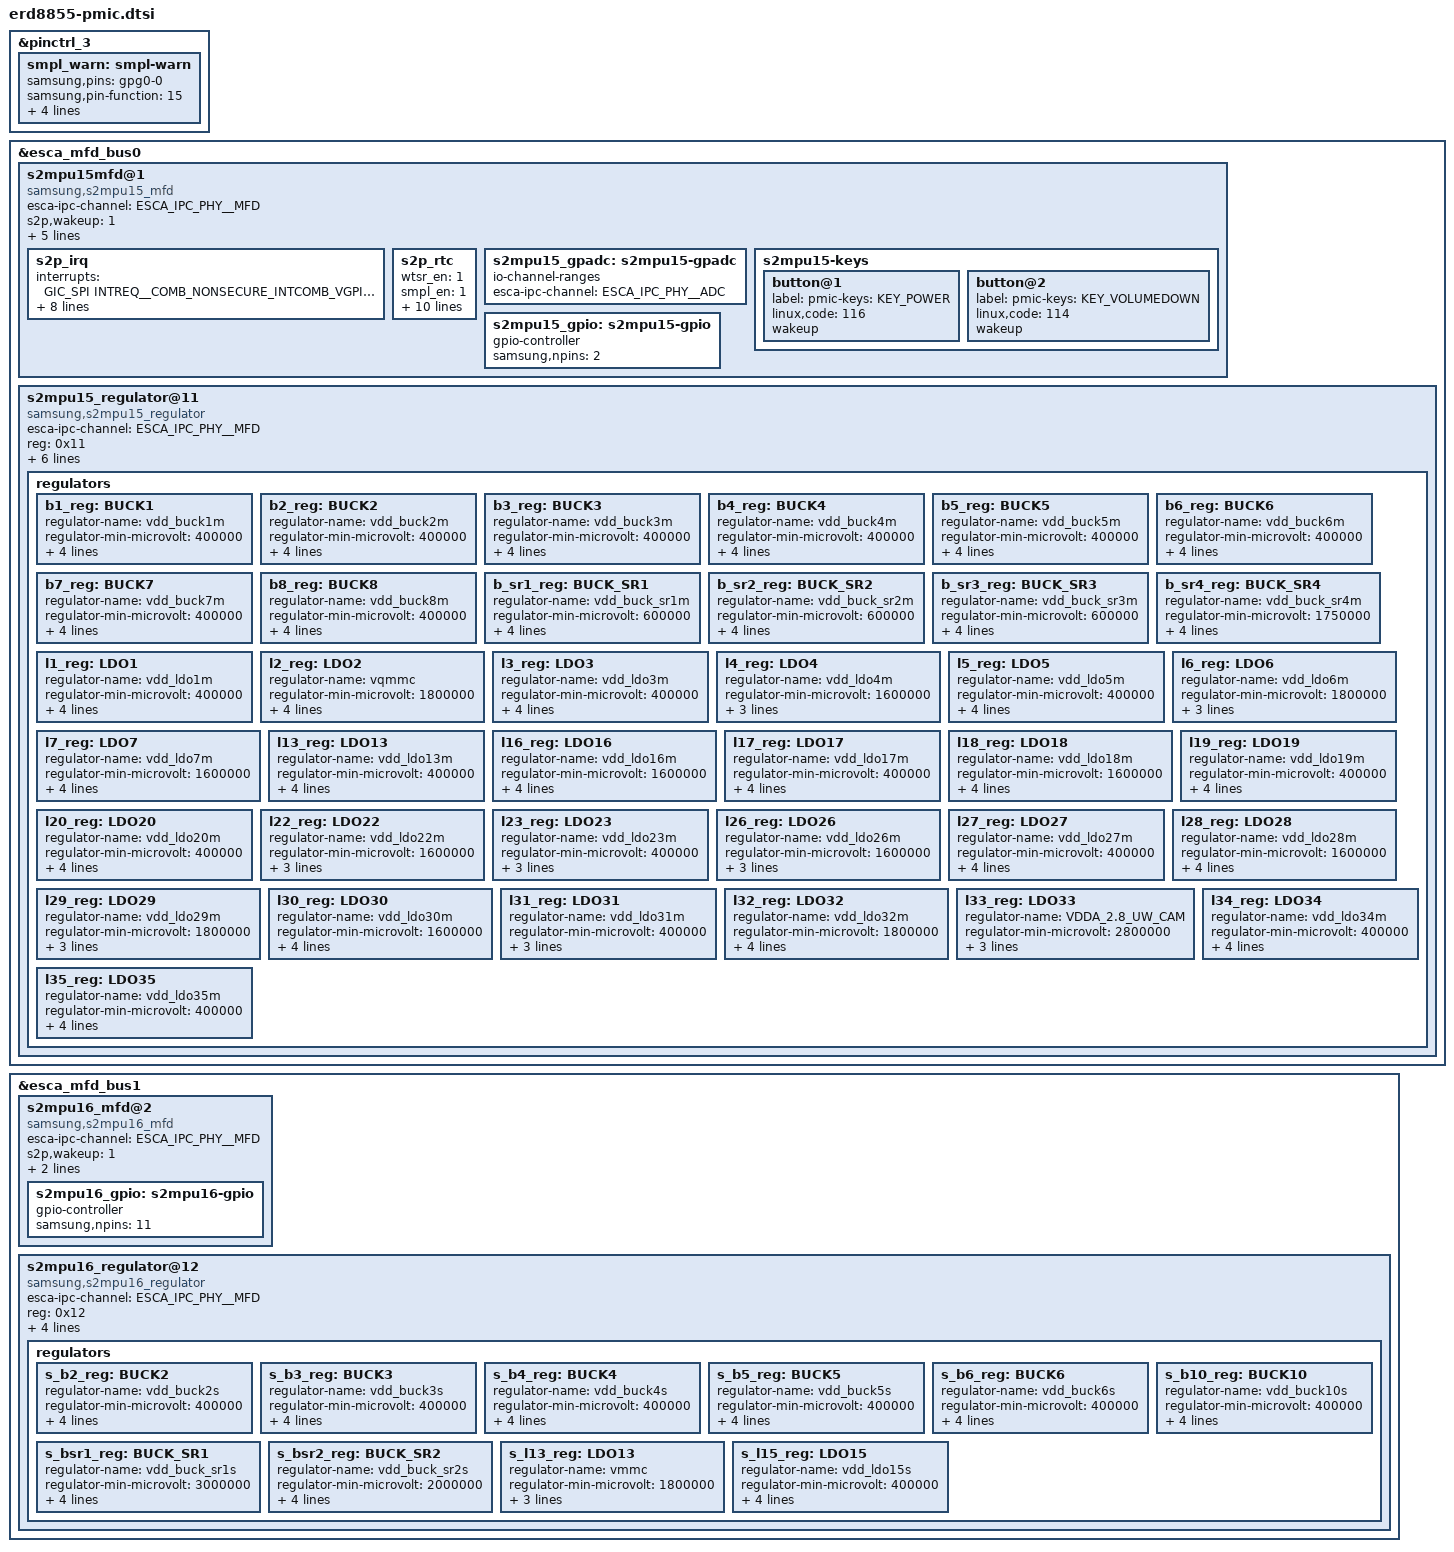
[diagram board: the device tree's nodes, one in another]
/*
 * SAMSUNG S5E8855 SOC PMIC device tree source
 *
 * Copyright (c) 2024 Samsung Electronics Co., Ltd.
 *             http://www.samsung.com
 *
 * SAMSUNG S5E8855 SOC PMIC device nodes are listed in this file.
 * EXYNOS based board files can include this file and provide
 * values for board specfic bindings.
 *
 * This program is free software; you can redistribute it and/or modify
 * it under the terms of the GNU General Public License version 2 as
 * published by the Free Software Foundation.
 */
#include <dt-bindings/soc/samsung/s5e8855-esca-ipc.h>

#define FCCM	1
#define AUTO	2

#define MAIN_ONSRC_ADDR		0x0514
#define MAIN_OFFSRC_ADDR	0x0516
#define SUB_OFFSRC_ADDR		0x0511

&pinctrl_3 {
	smpl_warn: smpl-warn {
		samsung,pins = "gpg0-0";
		samsung,pin-function = <15>;
		samsung,pin-pud = <0>;
		samsung,pin-drv = <0>;
		samsung,pin-con-pdn = <3>;
		samsung,pin-pud-pdn = <0>;
	};
};

&esca_mfd_bus0 {
	status = "okay";
	#address-cells = <1>;
	#size-cells = <0>;

	s2mpu15mfd@1 {
		compatible = "samsung,s2mpu15_mfd";
		esca-ipc-channel = <ESCA_IPC_PHY__MFD>;
		s2p,wakeup = <1>;
		reg = <0x01>;
		sid = <0>;
		pinctrl-names = "default";
		pinctrl-0 = <&smpl_warn>;
		gpios = <&gpg0 0 0>;

		/* SMPL_WARN */
		smpl_warn_en = <1>; /* 1 : enable , 0 : disable */

		s2p_irq {
			interrupts = <GIC_SPI INTREQ__COMB_NONSECURE_INTCOMB_VGPIO2AP IRQ_TYPE_LEVEL_HIGH>;
			interrupt-parent = <&gic>;
			s2p,vgi_cnt = <5>;
			sysreg,spmi_master_pmic = <0x11960000>;
			sysreg,vgpio_monitor = <0>;
			sysreg,vgpio_monitor2 = <4>;		//offset 4 for spmi_master_pmic_ap
			sysreg,intcomb_vgpio2ap = <0x11930000>;
			sysreg,intcomb_vgpio2pmu = <0x11950000>;
			sysreg,intc0_ipend = <0x0290>;
		};

		s2p_rtc {
			/* wtsr/smpl */
			wtsr_en = <1>; /* 1 : enable, 0 : disable */
			smpl_en = <1>; /* 1 : enable, 0 : disable */
			wtsr_timer_val = <3>;	/* 1000ms */
			smpl_timer_val = <0>;	/* 100ms */
			check_jigon_en = <0>; /* do not check jigon */
			/* If it's first boot, reset rtc to 1/1/2024 12:00:00(Mon) */
			init_time,sec = <0>;
			init_time,min = <0>;
			init_time,hour = <12>;
			init_time,mday = <1>;
			init_time,mon = <0>;
			init_time,year = <124>;
			init_time,wday = <1>;
		};

		s2mpu15_gpadc: s2mpu15-gpadc {
			#io-channel-cells = <1>;
			io-channel-ranges;
			esca-ipc-channel = <ESCA_IPC_PHY__ADC>;
		};

		s2mpu15-keys {
			button@1 {
				label = "pmic-keys: KEY_POWER";
				linux,code = <116>;
				wakeup;
			};

			button@2 {
				label = "pmic-keys: KEY_VOLUMEDOWN";
				linux,code = <114>;
				wakeup;
			};
		};

		s2mpu15_gpio: s2mpu15-gpio {
			gpio-controller;
			#gpio-cells = <2>;
			samsung,npins = <2>;
			status = "okay";
		}; /* s2mpu15-gpio */
	}; /* end of s2mpu15mfd@1 */

	s2mpu15_regulator@11 {
		compatible = "samsung,s2mpu15_regulator";
		esca-ipc-channel = <ESCA_IPC_PHY__MFD>;
		reg = <0x11>;
		sid = <0>;

		inst_acok_en = <1>; /* 1 : enable , 0 : disable */
		jig_reboot_en = <1>; /* 1 : enable , 0 : disable */
		pmic_src_no = <0>; /* pmic src index */
		on_src = <MAIN_ONSRC_ADDR 2>; /* start addr, num of addr */
		off_src = <MAIN_OFFSRC_ADDR 2>; /* start addr, num of addr */

		regulators {
			b1_reg: BUCK1 {
				regulator-name = "vdd_buck1m";
				regulator-min-microvolt = <400000>;
				regulator-max-microvolt = <1300000>;
				regulator-ramp-delay = <6000>;
				regulator-enable-mode = <1>;
				regulator-always-on;
			};

			b2_reg: BUCK2 {
				regulator-name = "vdd_buck2m";
				regulator-min-microvolt = <400000>;
				regulator-max-microvolt = <1300000>;
				regulator-ramp-delay = <6000>;
				regulator-enable-mode = <1>;
				regulator-always-on;
			};

			b3_reg: BUCK3 {
				regulator-name = "vdd_buck3m";
				regulator-min-microvolt = <400000>;
				regulator-max-microvolt = <1300000>;
				regulator-ramp-delay = <6000>;
				regulator-enable-mode = <1>;
				regulator-always-on;
			};

			b4_reg: BUCK4 {
				regulator-name = "vdd_buck4m";
				regulator-min-microvolt = <400000>;
				regulator-max-microvolt = <1300000>;
				regulator-ramp-delay = <6000>;
				regulator-enable-mode = <1>;
				regulator-always-on;
			};

			b5_reg: BUCK5 {
				regulator-name = "vdd_buck5m";
				regulator-min-microvolt = <400000>;
				regulator-max-microvolt = <1300000>;
				regulator-ramp-delay = <6000>;
				regulator-enable-mode = <1>;
				regulator-always-on;
			};

			b6_reg: BUCK6 {
				regulator-name = "vdd_buck6m";
				regulator-min-microvolt = <400000>;
				regulator-max-microvolt = <1300000>;
				regulator-ramp-delay = <6000>;
				regulator-enable-mode = <1>;
				regulator-always-on;
			};

			b7_reg: BUCK7 {
				regulator-name = "vdd_buck7m";
				regulator-min-microvolt = <400000>;
				regulator-max-microvolt = <1300000>;
				regulator-ramp-delay = <6000>;
				regulator-enable-mode = <1>;
				regulator-always-on;
			};

			b8_reg: BUCK8 {
				regulator-name = "vdd_buck8m";
				regulator-min-microvolt = <400000>;
				regulator-max-microvolt = <1300000>;
				regulator-ramp-delay = <6000>;
				regulator-enable-mode = <3>;
				regulator-always-on;
			};

			b_sr1_reg: BUCK_SR1 {
				regulator-name = "vdd_buck_sr1m";
				regulator-min-microvolt = <600000>;
				regulator-max-microvolt = <1350000>;
				regulator-ramp-delay = <6000>;
				regulator-enable-mode = <3>;
				regulator-always-on;
			};

			b_sr2_reg: BUCK_SR2 {
				regulator-name = "vdd_buck_sr2m";
				regulator-min-microvolt = <600000>;
				regulator-max-microvolt = <1350000>;
				regulator-ramp-delay = <6000>;
				regulator-enable-mode = <3>;
				regulator-always-on;
			};

			b_sr3_reg: BUCK_SR3 {
				regulator-name = "vdd_buck_sr3m";
				regulator-min-microvolt = <600000>;
				regulator-max-microvolt = <1350000>;
				regulator-ramp-delay = <6000>;
				regulator-enable-mode = <3>;
				regulator-always-on;
			};

			b_sr4_reg: BUCK_SR4 {
				regulator-name = "vdd_buck_sr4m";
				regulator-min-microvolt = <1750000>;
				regulator-max-microvolt = <2000000>;
				regulator-ramp-delay = <6000>;
				regulator-enable-mode = <3>;
				regulator-always-on;
			};

			l1_reg: LDO1 {
				regulator-name = "vdd_ldo1m";
				regulator-min-microvolt = <400000>;
				regulator-max-microvolt = <1300000>;
				regulator-ramp-delay = <12000>;
				regulator-enable-mode = <3>;
				regulator-always-on;
			};

			l2_reg: LDO2 {
				regulator-name = "vqmmc";
				regulator-min-microvolt = <1800000>;
				regulator-max-microvolt = <3375000>;
				regulator-ramp-delay = <12000>;
				regulator-enable-mode = <3>;
				regulator-always-on;
			};

			l3_reg: LDO3 {
				regulator-name = "vdd_ldo3m";
				regulator-min-microvolt = <400000>;
				regulator-max-microvolt = <1300000>;
				regulator-ramp-delay = <12000>;
				regulator-enable-mode = <1>;
				regulator-always-on;
			};

			l4_reg: LDO4 {
				regulator-name = "vdd_ldo4m";
				regulator-min-microvolt = <1600000>;
				regulator-max-microvolt = <1950000>;
				regulator-ramp-delay = <12000>;
				regulator-enable-mode = <3>;
			};

			l5_reg: LDO5 {
				regulator-name = "vdd_ldo5m";
				regulator-min-microvolt = <400000>;
				regulator-max-microvolt = <1300000>;
				regulator-ramp-delay = <12000>;
				regulator-enable-mode = <1>;
				regulator-always-on;
			};

			l6_reg: LDO6 {
				regulator-name = "vdd_ldo6m";
				regulator-min-microvolt = <1800000>;
				regulator-max-microvolt = <3375000>;
				regulator-ramp-delay = <12000>;
				regulator-enable-mode = <3>;
			};

			l7_reg: LDO7 {
				regulator-name = "vdd_ldo7m";
				regulator-min-microvolt = <1600000>;
				regulator-max-microvolt = <1950000>;
				regulator-ramp-delay = <12000>;
				regulator-enable-mode = <3>;
				regulator-always-on;
			};
/*
			l8_reg: LDO8 {
				regulator-name = "vdd_ldo8m";
				regulator-min-microvolt = <400000>;
				regulator-max-microvolt = <1300000>;
				regulator-ramp-delay = <12000>;
				regulator-enable-mode = <3>;
				regulator-always-on;
			};

			l9_reg: LDO9 {
				regulator-name = "vdd_ldo9m";
				regulator-min-microvolt = <400000>;
				regulator-max-microvolt = <1300000>;
				regulator-ramp-delay = <12000>;
				regulator-enable-mode = <3>;
				regulator-always-on;
			};

			l10_reg: LDO10 {
				regulator-name = "vdd_ldo10m";
				regulator-min-microvolt = <1800000>;
				regulator-max-microvolt = <3375000>;
				regulator-ramp-delay = <12000>;
				regulator-enable-mode = <3>;
				regulator-always-on;
			};

			l11_reg: LDO11 {
				regulator-name = "vdd_ldo11m";
				regulator-min-microvolt = <1800000>;
				regulator-max-microvolt = <3375000>;
				regulator-ramp-delay = <12000>;
				regulator-enable-mode = <3>;
				regulator-always-on;
			};

			l12_reg: LDO12 {
				regulator-name = "vdd_ldo12m";
				regulator-min-microvolt = <400000>;
				regulator-max-microvolt = <1300000>;
				regulator-ramp-delay = <12000>;
				regulator-enable-mode = <3>;
				regulator-always-on;
			};
*/
			l13_reg: LDO13 {
				regulator-name = "vdd_ldo13m";
				regulator-min-microvolt = <400000>;
				regulator-max-microvolt = <1300000>;
				regulator-ramp-delay = <12000>;
				regulator-enable-mode = <1>;
				regulator-always-on;
			};
/*
			l14_reg: LDO14 {
				regulator-name = "vdd_ldo14m";
				regulator-min-microvolt = <400000>;
				regulator-max-microvolt = <1300000>;
				regulator-ramp-delay = <12000>;
				regulator-enable-mode = <3>;
				regulator-always-on;
			};

			l15_reg: LDO15 {
				regulator-name = "vdd_ldo15m";
				regulator-min-microvolt = <400000>;
				regulator-max-microvolt = <1300000>;
				regulator-ramp-delay = <12000>;
				regulator-enable-mode = <3>;
				regulator-always-on;
			};
*/
			l16_reg: LDO16 {
				regulator-name = "vdd_ldo16m";
				regulator-min-microvolt = <1600000>;
				regulator-max-microvolt = <1950000>;
				regulator-ramp-delay = <12000>;
				regulator-enable-mode = <3>;
				regulator-always-on;
			};

			l17_reg: LDO17 {
				regulator-name = "vdd_ldo17m";
				regulator-min-microvolt = <400000>;
				regulator-max-microvolt = <1300000>;
				regulator-ramp-delay = <12000>;
				regulator-enable-mode = <3>;
				regulator-always-on;
			};

			l18_reg: LDO18 {
				regulator-name = "vdd_ldo18m";
				regulator-min-microvolt = <1600000>;
				regulator-max-microvolt = <1950000>;
				regulator-ramp-delay = <12000>;
				regulator-enable-mode = <3>;
				regulator-always-on;
			};

			l19_reg: LDO19 {
				regulator-name = "vdd_ldo19m";
				regulator-min-microvolt = <400000>;
				regulator-max-microvolt = <1300000>;
				regulator-ramp-delay = <12000>;
				regulator-enable-mode = <3>;
				regulator-always-on;
			};

			l20_reg: LDO20 {
				regulator-name = "vdd_ldo20m";
				regulator-min-microvolt = <400000>;
				regulator-max-microvolt = <1300000>;
				regulator-ramp-delay = <12000>;
				regulator-enable-mode = <1>;
				regulator-always-on;
			};
/*
			l21_reg: LDO21 {
				regulator-name = "vdd_ldo21m";
				regulator-min-microvolt = <400000>;
				regulator-max-microvolt = <1300000>;
				regulator-ramp-delay = <12000>;
				regulator-enable-mode = <3>;
				regulator-always-on;
			};
*/
			l22_reg: LDO22 {
				regulator-name = "vdd_ldo22m";
				regulator-min-microvolt = <1600000>;
				regulator-max-microvolt = <1950000>;
				regulator-ramp-delay = <12000>;
				regulator-enable-mode = <3>;
			};

			l23_reg: LDO23 {
				regulator-name = "vdd_ldo23m";
				regulator-min-microvolt = <400000>;
				regulator-max-microvolt = <1300000>;
				regulator-ramp-delay = <12000>;
				regulator-enable-mode = <3>;
			};
/*
			l24_reg: LDO24 {
				regulator-name = "vdd_ldo24m";
				regulator-min-microvolt = <1600000>;
				regulator-max-microvolt = <1950000>;
				regulator-ramp-delay = <12000>;
				regulator-enable-mode = <3>;
				regulator-always-on;
			};

			l25_reg: LDO25 {
				regulator-name = "vdd_ldo25m";
				regulator-min-microvolt = <400000>;
				regulator-max-microvolt = <1300000>;
				regulator-ramp-delay = <12000>;
				regulator-enable-mode = <3>;
				regulator-always-on;
			};
*/
			l26_reg: LDO26 {
				regulator-name = "vdd_ldo26m";
				regulator-min-microvolt = <1600000>;
				regulator-max-microvolt = <1950000>;
				regulator-ramp-delay = <12000>;
				regulator-enable-mode = <3>;
			};

			l27_reg: LDO27 {
				regulator-name = "vdd_ldo27m";
				regulator-min-microvolt = <400000>;
				regulator-max-microvolt = <1300000>;
				regulator-ramp-delay = <12000>;
				regulator-enable-mode = <1>;
				regulator-always-on;
			};

			l28_reg: LDO28 {
				regulator-name = "vdd_ldo28m";
				regulator-min-microvolt = <1600000>;
				regulator-max-microvolt = <1950000>;
				regulator-ramp-delay = <12000>;
				regulator-enable-mode = <3>;
				regulator-always-on;
			};

			l29_reg: LDO29 {
				regulator-name = "vdd_ldo29m";
				regulator-min-microvolt = <1800000>;
				regulator-max-microvolt = <3375000>;
				regulator-ramp-delay = <12000>;
				regulator-enable-mode = <3>;
			};

			l30_reg: LDO30 {
				regulator-name = "vdd_ldo30m";
				regulator-min-microvolt = <1600000>;
				regulator-max-microvolt = <1950000>;
				regulator-ramp-delay = <12000>;
				regulator-enable-mode = <3>;
				regulator-always-on;
			};

			l31_reg: LDO31 {
				regulator-name = "vdd_ldo31m";
				regulator-min-microvolt = <400000>;
				regulator-max-microvolt = <1300000>;
				regulator-ramp-delay = <12000>;
				regulator-enable-mode = <3>;
			};

			l32_reg: LDO32 {
				regulator-name = "vdd_ldo32m";
				regulator-min-microvolt = <1800000>;
				regulator-max-microvolt = <3375000>;
				regulator-ramp-delay = <12000>;
				regulator-enable-mode = <3>;
				regulator-always-on;
			};

			l33_reg: LDO33 {
				regulator-name = "VDDA_2.8_UW_CAM";
				regulator-min-microvolt = <2800000>;
				regulator-max-microvolt = <2800000>;
				regulator-ramp-delay = <12000>;
				regulator-enable-mode = <3>;
			};

			l34_reg: LDO34 {
				regulator-name = "vdd_ldo34m";
				regulator-min-microvolt = <400000>;
				regulator-max-microvolt = <1300000>;
				regulator-ramp-delay = <12000>;
				regulator-enable-mode = <1>;
				regulator-always-on;
			};

			l35_reg: LDO35 {
				regulator-name = "vdd_ldo35m";
				regulator-min-microvolt = <400000>;
				regulator-max-microvolt = <1300000>;
				regulator-ramp-delay = <12000>;
				regulator-enable-mode = <1>;
				regulator-always-on;
			};
		}; /* end of regulators */
	}; /* end of s2mpu15_regulator@11 */
}; /* end of esca_mfd_bus0 */

&esca_mfd_bus1 {
	status = "okay";
	#address-cells = <1>;
	#size-cells = <0>;

	s2mpu16_mfd@2 {
		compatible = "samsung,s2mpu16_mfd";
		esca-ipc-channel = <ESCA_IPC_PHY__MFD>;
		s2p,wakeup = <1>;
		reg = <0x02>;
		sid = <1>;

		s2mpu16_gpio: s2mpu16-gpio {
			gpio-controller;
			#gpio-cells = <2>;
			samsung,npins = <11>;
			status = "okay";
		}; /* s2mpu16-gpio */
	}; /* end of s2mpu16_mfd@2 */

	s2mpu16_regulator@12 {
		compatible = "samsung,s2mpu16_regulator";
		esca-ipc-channel = <ESCA_IPC_PHY__MFD>;
		reg = <0x12>;
		sid = <1>;
		wtsr_en = <1>; /* 0 : disable, 1: enable */
		pmic_src_no = <1>; /* pmic src index */
		off_src = <SUB_OFFSRC_ADDR 2>; /* start addr, num of addr */

		regulators {
/*
			s_b1_reg: BUCK1 {
				regulator-name = "vdd_buck1s";
				regulator-min-microvolt = <400000>;
				regulator-max-microvolt = <1300000>;
				regulator-ramp-delay = <6000>;
				regulator-enable-mode = <3>;
				regulator-always-on;
			};
*/
			s_b2_reg: BUCK2 {
				regulator-name = "vdd_buck2s";
				regulator-min-microvolt = <400000>;
				regulator-max-microvolt = <1300000>;
				regulator-ramp-delay = <6000>;
				regulator-enable-mode = <1>;
				regulator-always-on;
			};

			s_b3_reg: BUCK3 {
				regulator-name = "vdd_buck3s";
				regulator-min-microvolt = <400000>;
				regulator-max-microvolt = <1300000>;
				regulator-ramp-delay = <6000>;
				regulator-enable-mode = <1>;
				regulator-always-on;
			};

			s_b4_reg: BUCK4 {
				regulator-name = "vdd_buck4s";
				regulator-min-microvolt = <400000>;
				regulator-max-microvolt = <1300000>;
				regulator-ramp-delay = <6000>;
				regulator-enable-mode = <1>;
				regulator-always-on;
			};

			s_b5_reg: BUCK5 {
				regulator-name = "vdd_buck5s";
				regulator-min-microvolt = <400000>;
				regulator-max-microvolt = <1300000>;
				regulator-ramp-delay = <6000>;
				regulator-enable-mode = <1>;
				regulator-always-on;
			};

			s_b6_reg: BUCK6 {
				regulator-name = "vdd_buck6s";
				regulator-min-microvolt = <400000>;
				regulator-max-microvolt = <1300000>;
				regulator-ramp-delay = <6000>;
				regulator-enable-mode = <1>;
				regulator-always-on;
			};
/*
			s_b7_reg: BUCK7 {
				regulator-name = "vdd_buck7s";
				regulator-min-microvolt = <400000>;
				regulator-max-microvolt = <1300000>;
				regulator-ramp-delay = <6000>;
				regulator-enable-mode = <3>;
				regulator-always-on;
			};

			s_b8_reg: BUCK8 {
				regulator-name = "vdd_buck8s";
				regulator-min-microvolt = <400000>;
				regulator-max-microvolt = <1300000>;
				regulator-ramp-delay = <6000>;
				regulator-enable-mode = <3>;
				regulator-always-on;
			};

			s_b9_reg: BUCK9 {
				regulator-name = "vdd_buck9s";
				regulator-min-microvolt = <400000>;
				regulator-max-microvolt = <1300000>;
				regulator-ramp-delay = <6000>;
				regulator-enable-mode = <3>;
				regulator-always-on;
			};
*/
			s_b10_reg: BUCK10 {
				regulator-name = "vdd_buck10s";
				regulator-min-microvolt = <400000>;
				regulator-max-microvolt = <1300000>;
				regulator-ramp-delay = <6000>;
				regulator-enable-mode = <1>;
				regulator-always-on;
			};

			s_bsr1_reg: BUCK_SR1 {
				regulator-name = "vdd_buck_sr1s";
				regulator-min-microvolt = <3000000>;
				regulator-max-microvolt = <3600000>;
				regulator-ramp-delay = <6000>;
				regulator-enable-mode = <3>;
				regulator-always-on;
			};

			s_bsr2_reg: BUCK_SR2 {
				regulator-name = "vdd_buck_sr2s";
				regulator-min-microvolt = <2000000>;
				regulator-max-microvolt = <2400000>;
				regulator-ramp-delay = <6000>;
				regulator-enable-mode = <3>;
				regulator-always-on;
			};
/*
			s_l1_reg: LDO1 {
				regulator-name = "vdd_ldo1s";
				regulator-min-microvolt = <400000>;
				regulator-max-microvolt = <1300000>;
				regulator-ramp-delay = <12000>;
				regulator-enable-mode = <3>;
				regulator-always-on;
			};

			s_l2_reg: LDO2 {
				regulator-name = "vdd_ldo2s";
				regulator-min-microvolt = <400000>;
				regulator-max-microvolt = <1300000>;
				regulator-ramp-delay = <12000>;
				regulator-enable-mode = <3>;
				regulator-always-on;
			};

			s_l3_reg: LDO3 {
				regulator-name = "vdd_ldo3s";
				regulator-min-microvolt = <1600000>;
				regulator-max-microvolt = <1950000>;
				regulator-ramp-delay = <12000>;
				regulator-enable-mode = <3>;
				regulator-always-on;
			};

			s_l4_reg: LDO4 {
				regulator-name = "vdd_ldo4s";
				regulator-min-microvolt = <400000>;
				regulator-max-microvolt = <1300000>;
				regulator-ramp-delay = <12000>;
				regulator-enable-mode = <3>;
				regulator-always-on;
			};

			s_l5_reg: LDO5 {
				regulator-name = "vdd_ldo5s";
				regulator-min-microvolt = <400000>;
				regulator-max-microvolt = <1300000>;
				regulator-ramp-delay = <12000>;
				regulator-enable-mode = <3>;
				regulator-always-on;
			};

			s_l6_reg: LDO6 {
				regulator-name = "vdd_ldo6s";
				regulator-min-microvolt = <400000>;
				regulator-max-microvolt = <1300000>;
				regulator-ramp-delay = <12000>;
				regulator-enable-mode = <3>;
				regulator-always-on;
			};

			s_l7_reg: LDO7 {
				regulator-name = "vdd_ldo7s";
				regulator-min-microvolt = <400000>;
				regulator-max-microvolt = <1300000>;
				regulator-ramp-delay = <12000>;
				regulator-enable-mode = <3>;
				regulator-always-on;
			};

			s_l8_reg: LDO8 {
				regulator-name = "vdd_ldo8s";
				regulator-min-microvolt = <1600000>;
				regulator-max-microvolt = <1950000>;
				regulator-ramp-delay = <12000>;
				regulator-enable-mode = <3>;
				regulator-always-on;
			};

			s_l9_reg: LDO9 {
				regulator-name = "vdd_ldo9s";
				regulator-min-microvolt = <1600000>;
				regulator-max-microvolt = <1950000>;
				regulator-ramp-delay = <12000>;
				regulator-enable-mode = <3>;
				regulator-always-on;
			};

			s_l10_reg: LDO10 {
				regulator-name = "vdd_ldo10s";
				regulator-min-microvolt = <1600000>;
				regulator-max-microvolt = <1950000>;
				regulator-ramp-delay = <12000>;
				regulator-enable-mode = <3>;
				regulator-always-on;
			};

			s_l11_reg: LDO11 {
				regulator-name = "vdd_ldo11s";
				regulator-min-microvolt = <1800000>;
				regulator-max-microvolt = <3375000>;
				regulator-ramp-delay = <12000>;
				regulator-enable-mode = <3>;
				regulator-always-on;
			};

			s_l12_reg: LDO12 {
				regulator-name = "vdd_ldo12s";
				regulator-min-microvolt = <1800000>;
				regulator-max-microvolt = <3375000>;
				regulator-ramp-delay = <12000>;
				regulator-enable-mode = <3>;
				regulator-always-on;
			};
*/
			s_l13_reg: LDO13 {
				regulator-name = "vmmc";
				regulator-min-microvolt = <1800000>;
				regulator-max-microvolt = <3375000>;
				regulator-ramp-delay = <12000>;
				regulator-enable-mode = <3>;
			};
/*
			s_l14_reg: LDO14 {
				regulator-name = "vdd_ldo14s";
				regulator-min-microvolt = <400000>;
				regulator-max-microvolt = <1300000>;
				regulator-ramp-delay = <12000>;
				regulator-enable-mode = <3>;
				regulator-always-on;
			};
*/
			s_l15_reg: LDO15 {
				regulator-name = "vdd_ldo15s";
				regulator-min-microvolt = <400000>;
				regulator-max-microvolt = <1300000>;
				regulator-ramp-delay = <12000>;
				regulator-enable-mode = <3>;
				regulator-always-on;
			};
		}; /* end of regulators */
	}; /* end of s2mpu16_regulator@12 */
}; /* end of esca_mfd_bus1 */
